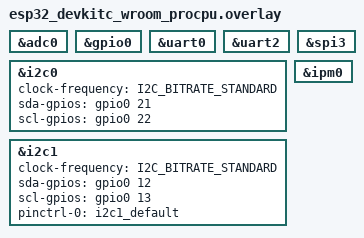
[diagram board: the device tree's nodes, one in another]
adc_0: &adc0 {
    status = "okay";
};

gpio_0: &gpio0 {
	status = "okay";
};

uart_0: &uart0 { };

uart_2: &uart2 { 
	status = "okay";
};

spi_3: &spi3 { };

i2c_0: &i2c0 { 
	clock-frequency = <I2C_BITRATE_STANDARD>;
	sda-gpios = <&gpio0 21 GPIO_PULL_UP>;
	scl-gpios = <&gpio0 22 GPIO_PULL_UP>;
};

i2c_1: &i2c1 {
	status = "okay";
	clock-frequency = <I2C_BITRATE_STANDARD>;
	sda-gpios = <&gpio0 12 GPIO_OPEN_DRAIN>;
	scl-gpios = <&gpio0 13 GPIO_OPEN_DRAIN>;
	pinctrl-0 = <&i2c1_default>;
	pinctrl-names = "default";
};

&ipm0 { 
	status = "okay";
};

/*
&flash {
    part0: partition@3ff42000{
        label = "nvs";
        reg = <0x1000 0x4000>;
    };
    part1: partition@4000 {
        label = "otadata";
        reg = <0x4000 0x2000>;
    };
    part2: partition@6000 {
        label = "app";
        reg = <0x6000 0x100000>;
        type = "app";
    };
    part3: partition@100000 {
        label = "spiffs";
        reg = <0x100000 0x80000>;
        type = "spiffs";
    };
};
*/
